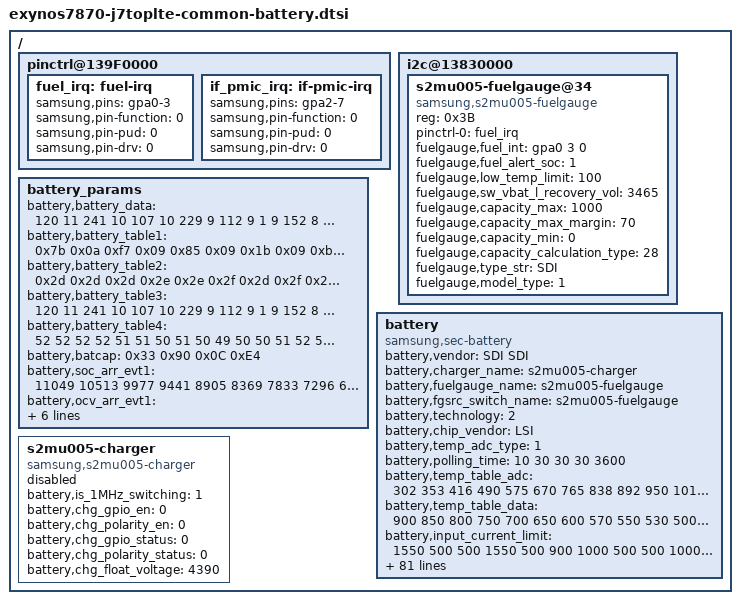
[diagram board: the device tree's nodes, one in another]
/*
 * SAMSUNG UNIVERSAL5433 board device tree source
 *
 * Copyright (c) 2013 Samsung Electronics Co., Ltd.
 *		http://www.samsung.com
 *
 * This program is free software; you can redistribute it and/or modify
 * it under the terms of the GNU General Public License version 2 as
 * published by the Free Software Foundation.
*/

/ {
	pinctrl@139F0000 {
		fuel_irq: fuel-irq {
			samsung,pins = "gpa0-3";
			samsung,pin-function = <0>;
			samsung,pin-pud = <0>;
			samsung,pin-drv = <0>;
		};
	};

	pinctrl@139F0000 {
		if_pmic_irq: if-pmic-irq {
			samsung,pins = "gpa2-7";
			samsung,pin-function = <0>;
			samsung,pin-pud = <0>;
			samsung,pin-drv = <0>;
		};
	};

	i2c@13830000 {
		status = "okay";
		s2mu005-fuelgauge@34 {
			compatible = "samsung,s2mu005-fuelgauge";
			reg = <0x3B>;
			pinctrl-names = "default";
			pinctrl-0 = <&fuel_irq>;
			fuelgauge,fuel_int = <&gpa0 3 0>;
			fuelgauge,fuel_alert_soc = <1>;
			fuelgauge,low_temp_limit = <100>;
			fuelgauge,sw_vbat_l_recovery_vol = <3465>;
			fuelgauge,capacity_max = <1000>;
			fuelgauge,capacity_max_margin = <70>;
			fuelgauge,capacity_min = <0>;
			fuelgauge,capacity_calculation_type = <28>;
			fuelgauge,type_str = "SDI";
			fuelgauge,model_type = <1>;
		};
	};

	battery_params {
			battery,battery_data =
			<
				/***** battery data for 4.35 *****/
				/* battery,battery_table3 */
				120 11 241 10 107 10 229 9 112 9 1 9 152 8 41 8 195
				7 134 7 45 7 209 6 154 6 114 6 83 6 58 6 29 6 246 5
				193 5 145 5 14 5 223 1 49 9 191 8 77 8 219 7 105 7 247
				6 132 6 19 6 161 5 46 5 188 4 74 4 216 3 102 3 244 2
				130 2 16 2 158 1 44 1 186 0 72 0 214 15

				/* battery,battery_table4 */
				52 52 52 52 51 51 50 51 50 49 50 50
				51 52 54 56 60 64 73 87 111 106

				/* battery,batcap */
				0x33 0x90 0x0C 0xE4 /* [0x0F] [0x0E] [0x11] [0x10] */
				/* battery,accum */
				0x66 0x08 /* [0x44] [0x45] */

				/* battery,soc_arr_val */
				11488 10931 10374 9818 9261 8704 8147 7591 7034 6477 5920 5363 4807 4250 3693 3136 2580 2023 1466 910 353 (-204)
				/* battery,ocv_arr_val */
				44335 43678 43021 42368 41795 41254 40740 40199 39701 39405 38972 38521 38253 38059 37907 37785 37640 37452 37193 36957 36319 32338

				/***** battery data for 4.33 *****/
				/* battery,battery_table3 */
				95 11 220 10 89 10 215 9 100 9 248 8
				145 8 29 8 193 7 134 7 46 7 210 6
				158 6 119 6 88 6 62 6 30 6 246 5
				192 5 144 5 3 5 135 1 167 8 59 8
				208 7 100 7 249 6 141 6 34 6 182 5
				75 5 223 4 116 4 8 4 157 3 49 3
				198 2 90 2 239 1 131 1 24 1 172 0
				65 0 213 15

				/* battery,battery_table4 */
				49 49 49 49 49 49 49 49 49 48 48
				48 49 49 50 52 53 55 57 59 68 145

				/* battery,batcap */
				0x32 0xB4 0x0C 0xAD /* [0x0F] [0x0E] [0x11] [0x10] */
				/* battery,accum */
				0xD1 0x07 /* [0x44] [0x45] */

				/* battery,soc_arr_val */
				10814 10290 9765 9240 8715 8189 7665 7140 6615 6090 5565 5040 4516 3991 3466 2940 2416 1891 1366 840 316 (-208)
				/* battery,ocv_arr_val */
				44212 43573 42934 42300 41739 41209 40706 40144 39691 39403 38974 38527 38270 38080 37929 37803 37647 37453 37188 36955 36263 31907

				/***** battery data for 4.31 *****/
				/* battery,battery_table3 */
				45 11 175 10 50 10 181 9 70 9 221 8
				127 8 253 7 186 7 117 7 26 7 200 6
				151 6 114 6 85 6 59 6 27 6 244 5
				190 5 144 5 2 5 112 1 173 8 65 8
				213 7 105 7 254 6 146 6 38 6 186 5
				78 5 226 4 118 4 10 4 159 3 51 3
				199 2 91 2 239 1 131 1 24 1 172 0
				64 0 212 15

				/* battery,battery_table4 */
				48 48 49 49 49 49 48 48 48 48 47
				48 48 49 50 51 52 54 57 60 69 156

				/* battery,batcap */
				0x31 0xEC 0x0C 0x7B /* [0x0F] [0x0E] [0x11] [0x10] */
				/* battery,accum */
				0xD1 0x07 /* [0x44] [0x45] */

				/* battery,soc_arr_val */
				10845 10318 9791 9265 8738 8211 7685 7158 6631 6105 5578 5051 4525 3998 3472 2945 2418 1892 1365 838 312 (-214)
				/* battery,ocv_arr_val */
				43970 43356 42742 42133 41590 41080 40621 39987 39657 39323 38878 38476 38238 38058 37914 37790 37633 37440 37176 36952 36259 31798

				/***** battery data for 4.29 *****/
				/* battery,battery_table3 */
				254 10 133 10 12 10 147 9 39 9 194 8
				109 8 229 7 176 7 100 7 8 7 190 6
				145 6 110 6 81 6 57 6 26 6 243 5
				189 5 144 5 9 5 160 1 172 8 64 8
				213 7 105 7 253 6 145 6 37 6 186 5
				78 5 226 4 118 4 10 4 159 3 51 3
				199 2 91 2 240 1 132 1 24 1 172 0
				64 0 213 15

				/* battery,battery_table4 */
				101 101 100 99 100 100 99 99 99 98 99
				99 99 100 102 104 106 109 113 120 132 178

				/* battery,batcap */
				0x31 0x24 0x0C 0x49 /* [0x0F] [0x0E] [0x11] [0x10] */
				/* battery,accum */
				0xD1 0x07 /* [0x44] [0x45] */

				/* battery,soc_arr_val */
				10841 10315 9789 9262 8736 8210 7683 7157 6631 6104 5578 5051 4525 3999 3472 2945 2420 1893 1366 840 314 (-212)

				/* battery,ocv_arr_val */
				43742 43150 42558 41968 41441 40949 40533 39869 39610 39239 38787 38429 38207 38035 37898 37779 37627 37436 37172 36953 36293 32032

				/***** battery data for 4.24 *****/
				/* battery,battery_table3 */
				135 10 24 10 169 9 58 9 215 8 133 8
				1 8 191 7 135 7 54 7 220 6 167 6
				129 6 99 6 74 6 49 6 17 6 233 5
				178 5 138 5 243 4 135 1 170 8 63 8
				211 7 103 7 251 6 144 6 36 6 184 5
				77 5 225 4 117 4 9 4 158 3 50 3
				198 2 91 2 239 1 131 1 24 1 172 0
				64 0 212 15

				/* battery,battery_table4 */
				95 95 95 95 95 95 95 95 94 94 95
				95 96 97 98 99 102 105 108 115 129 180

				/* battery,batcap */
				0x2E 0xE0 0x0B 0xB8 /* [0x0F] [0x0E] [0x11] [0x10] */

				/* battery,accum */
				0xD1 0x07 /* [0x44] [0x45] */

				/* battery,soc_arr_val */
				10832 10306 9780 9254 8728 8202 7675 7150 6624 6098 5572 5046 4521 3995 3469 2943 2417 1891 1365 839 313 (-213)

				/* battery,ocv_arr_val */
				43157 42615 42073 41532 41051 40648 40007 39682 39407 39014 38572 38318 38130 37982 37861 37740 37581 37386 37121 36925 36189 31910
			>;

			battery,battery_table1 =
				<0x7b 0x0a 0xf7 0x09 0x85 0x09 0x1b 0x09
				0xb4 0x08 0x60 0x08 0xd5 0x07 0xaa 0x07
				0x5e 0x07 0xf9 0x06 0xb7 0x06 0x8b 0x06
				0x68 0x06 0x4d 0x06 0x36 0x06 0x1a 0x06
				0xf2 0x05 0xbf 0x05 0x87 0x05 0x68 0x05
				0x66 0x05 0x33 0x02 0xc1 0x07 0x62 0x07
				0x03 0x07 0xa4 0x06 0x46 0x06 0xe7 0x05
				0x88 0x05 0x29 0x05 0xca 0x04 0x6b 0x04
				0x0c 0x04 0xad 0x03 0x4f 0x03 0xf0 0x02
				0x91 0x02 0x32 0x02 0xd3 0x01 0x74 0x01
				0x15 0x01 0xb6 0x00 0x57 0x00 0xf9 0x0f>;

			battery,battery_table2 =
				<0x2d 0x2d 0x2d 0x2e 0x2e 0x2f 0x2d
				0x2f 0x2f 0x2e 0x2f 0x2e 0x2e 0x2f 0x2e
				0x2e 0x2f 0x2f 0x2f 0x2e 0x2f 0x9a>;

			battery,battery_table3 =
				<120 11 241 10 107 10 229 9 112 9 1 9 152 8 41 8 195
				7 134 7 45 7 209 6 154 6 114 6 83 6 58 6 29 6 246 5
				193 5 145 5 14 5 223 1 49 9 191 8 77 8 219 7 105 7 247
				6 132 6 19 6 161 5 46 5 188 4 74 4 216 3 102 3 244 2
				130 2 16 2 158 1 44 1 186 0 72 0 214 15>;

			battery,battery_table4 = <52 52 52 52 51 51 50 51 50 49 50 50
									51 52 54 56 60 64 73 87 111 106>;

			battery,batcap = <0x33 0x90 0x0C 0xE4>; /* [0x0F] [0x0E] [0x11] [0x10] */

			battery,soc_arr_evt1 = <11049 10513 9977 9441 8905 8369 7833 7296 6760 6224 5688
						5152 4616 4080 3544 3008 2471 1935 1399 863 327 (-209)>;
			battery,ocv_arr_evt1 = <44691 43979 43267 42563 41956 41386 40863 40362 39764 39460 39008
						38545 38258 38059 37905 37794 37687 37510 37234 36953 36661 32596>;

			battery,soc_arr_evt2 = <11488 10931 10374 9818 9261 8704 8147 7591 7034 6477
								5920 5363 4807 4250 3693 3136 2580 2023 1466 910 353 (-204)>;
			battery,ocv_arr_evt2 = <44335 43678 43021 42368 41795 41254 40740 40199 39701 39405 38972
								38521 38253 38059 37907 37785 37640 37452 37193 36957 36319 32338>;

			battery,FG_Accumulative_rate_evt2 =<0x66 0x08>;
	};

	battery {
		status = "okay";

		pinctrl-names = "default";

		compatible = "samsung,sec-battery";
		battery,vendor = "SDI SDI";
		battery,charger_name = "s2mu005-charger";
		battery,fuelgauge_name = "s2mu005-fuelgauge";
		battery,fgsrc_switch_name = "s2mu005-fuelgauge";
		battery,technology = <2>; /* POWER_SUPPLY_TECHNOLOGY_LION */

		battery,chip_vendor = "LSI";
		battery,temp_adc_type = <1>; /* SEC_BATTERY_ADC_TYPE_AP */

		battery,polling_time = <10 30 30 30 3600>;

		battery,temp_table_adc = <302 353 416 490 575 670 765 838 892 950 1015 1090 1143 1214 1284 1359 1396 1437 1525 1610 1694 1825 1957 2047 2272 2497 2716 2842 2928 2966 3005 3103 3203 3267 3326 3408 3528 3629>;
		battery,temp_table_data = <900 850 800 750 700 650 600 570 550 530 500 480 470 450 430 410 400 390 370 350 330 300 270 250 200 150 100 70 50 40 30 0 (-30) (-50) (-70) (-100) (-150) (-200)>;

		battery,input_current_limit = <1550 500 500 1550 500 900 1000 500 500 1000 820 1550 1550 1550 1550 500 1300 300 700 1300 1500 300 80 500 1550 1400 1000 1550 1400 900 820 820 500 1000 820 820>;
		battery,fast_charging_current = <1750 0 500 1750 500 1200 1000 500 0 1200 1000 1750 1750 1750 1750 0 1300 300 700 1300 1500 300 80 0 1750 1200 1000 1750 1400 1200 1000 1000 0 0 1000 1000>;
		battery,full_check_current_1st = <330 0 330 330 330 330 330 330 0 330 330 330 330 330 0 0 330 330 330 330 330 330 0 330 330 330 330 0 330 330 330 0 330 330 330>;
		battery,full_check_current_2nd = <165 0 0 165 165 165 165 165 165 0 165 165 165 165 165 0 0 165 165 165 165 165 165 0 165 165 165 165 0 165 165 165 0 165 165 165>;

		battery,wireless_cc_cv = <86>;
		battery,inbat_voltage = <0>;

		battery,inbat_voltage_table_adc = <3120 3101 3061 3038 3001 2956 2920 2887 2856 2814
						2793 2754 2720 2677 2641 2613 2572 2531 2502 2467 2436>;
		battery,inbat_voltage_table_data = <438 435 430 425 420 415 410 405 400 395
						390 385 380 375 370 365 360 355 350 345 340>;

		battery,adc_check_count = <5>;

		battery,cable_check_type = <4>; /* SEC_BATTERY_CABLE_CHECK_PSY */
		battery,cable_source_type = <1>; /* SEC_BATTERY_CABLE_SOURCE_EXTERNAL */
		battery,polling_type = <1>; /* SEC_BATTERY_MONITOR_ALARM */
		battery,monitor_initial_count = <0>;

		battery,battery_check_type = <0>; /* SEC_BATTERY_CHECK_NONE */
		battery,check_count = <0>;

		battery,check_adc_max = <1440>;
		battery,check_adc_min = <0>;

		battery,ovp_uvlo_check_type = <3>; /* SEC_BATTERY_OVP_UVLO_CHGPOLLING */

		battery,thermal_source = <2>; /* SEC_BATTERY_THERMAL_SOURCE_ADC */

		battery,temp_check_type = <2>; /* SEC_BATTERY_TEMP_CHECK_TEMP */
		battery,temp_check_count = <1>;
		battery,temp_highlimit_threshold_normal = <800>;
		battery,temp_highlimit_recovery_normal = <750>;
		battery,temp_high_threshold_normal = <500>;
		battery,temp_high_recovery_normal = <450>;
		battery,temp_low_threshold_normal = <0>;
		battery,temp_low_recovery_normal = <50>;
		battery,temp_highlimit_threshold_lpm = <800>;
		battery,temp_highlimit_recovery_lpm = <750>;
		battery,temp_high_threshold_lpm = <500>;
		battery,temp_high_recovery_lpm = <450>;
		battery,temp_low_threshold_lpm = <0>;
		battery,temp_low_recovery_lpm = <50>;

		battery,full_check_type = <2>; /* SEC_BATTERY_FULLCHARGED_FG_CURRENT  */
		battery,full_check_type_2nd = <2>; /* SEC_BATTERY_FULLCHARGED_FG_CURRENT  */
		battery,full_check_count = <2>;
		battery,chg_gpio_full_check = <0>;
		battery,chg_polarity_full_check = <1>;

		/* SEC_BATTERY_FULL_CONDITION_SOC |
		   SEC_BATTERY_FULL_CONDITION_NOTIMEFULL |
		   SEC_BATTERY_FULL_CONDITION_VCELL */
		battery,full_condition_type = <13>;
		battery,full_condition_soc = <93>;
		battery,full_condition_vcell = <4250>;

		battery,recharge_check_count = <2>;
		battery,recharge_condition_type = <4>; /* SEC_BATTERY_RECHARGE_CONDITION_VCELL */
		battery,recharge_condition_soc = <98>;
		battery,recharge_condition_vcell = <4250>;

		battery,charging_total_time = <21600>; /* need to check */
		battery,recharging_total_time = <5400>; /* need to check */
		battery,charging_reset_time = <0>; /* need to check */
		battery,always_enable; /* need to check */

		battery,chg_float_voltage = <4350>;

		battery,standard_curr = <1750>;
		battery,expired_time = <15600>;
		battery,recharging_expired_time = <5400>;

		battery,self_discharging_temp_block = <600>;
		battery,self_discharging_volt_block = <4250>;
		battery,self_discharging_temp_recov = <550>;
		battery,self_discharging_temp_pollingtime = <400>;

		battery,swelling_high_temp_block = <410>;
		battery,swelling_high_temp_recov = <390>;
		battery,swelling_low_temp_2step_mode = <1>;
		battery,swelling_low_temp_block_1st = <150>;
		battery,swelling_low_temp_recov_1st = <200>;
		battery,swelling_low_temp_block_2nd = <50>;
		battery,swelling_low_temp_recov_2nd = <100>;

		battery,swelling_low_temp_current = <800>;
		battery,swelling_low_temp_topoff = <165>;
		battery,swelling_high_temp_current = <1200>;
		battery,swelling_high_temp_topoff = <165>;
		battery,swelling_drop_float_voltage = <4150>;
		battery,swelling_high_rechg_voltage = <4000>;
		battery,swelling_low_rechg_voltage = <4000>;

		battery,siop_input_limit_current = <1200>; /* need to check */
		battery,siop_charging_limit_current = <1000>; /* need to check */

		/* cycle, chg_float_voltage, recharge_condition_vcell, full_condition_vcell, full_condition_soc */
		battery,age_data = <0 4350 4250 4250 92	/*4.35*/
				200 4330 4230 4230 91	/*4.33*/
				250 4310 4210 4210 89	/*4.31*/
				300 4290 4190 4190 87	/*4.29*/
				1000 4240 4140 4140 83	/*4.24*/
				>;

		io-channels = <&exynos_adc 1>;
		io-channel-names = "adc-temp";
		#io-channel-cells = <1>;
		io-channel-ranges;
	};

	s2mu005-charger {
		status = "disable";
		compatible = "samsung,s2mu005-charger";
		battery,is_1MHz_switching = <1>;
		battery,chg_gpio_en = <0>;
		battery,chg_polarity_en = <0>;
		battery,chg_gpio_status = <0>;
		battery,chg_polarity_status = <0>;
		battery,chg_float_voltage = <4390>;
	};
};
